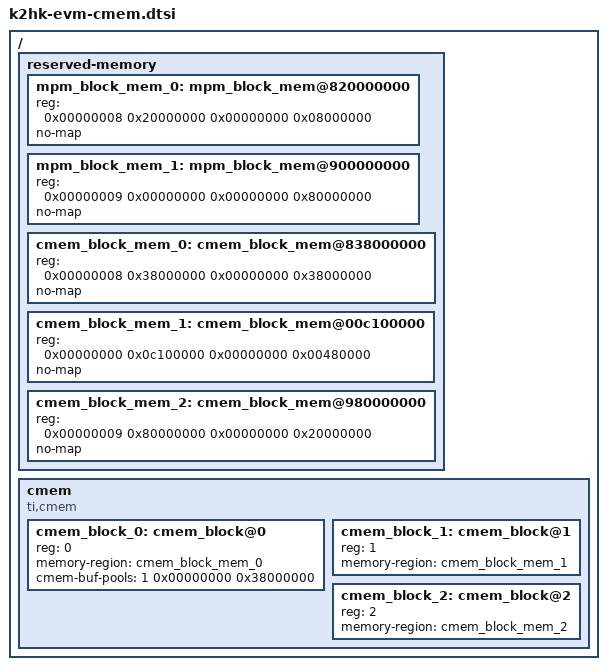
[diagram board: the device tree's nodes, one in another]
/ {
        reserved-memory {
                mpm_block_mem_0: mpm_block_mem@820000000 {
                        reg = <0x00000008 0x20000000 0x00000000 0x08000000>;
                        no-map;
                        status = "okay";
                };
                mpm_block_mem_1: mpm_block_mem@900000000 {
                        reg = <0x00000009 0x00000000 0x00000000 0x80000000>;
                        no-map;
                        status = "okay";
                };

                cmem_block_mem_0: cmem_block_mem@838000000 {
                        reg = <0x00000008 0x38000000 0x00000000 0x38000000>;
                        no-map;
                        status = "okay";
                };

                cmem_block_mem_1: cmem_block_mem@00c100000 {
                        reg = <0x00000000 0x0c100000 0x00000000 0x00480000>;
                        no-map;
                        status = "okay";
                };

                cmem_block_mem_2: cmem_block_mem@980000000 {
                        reg = <0x00000009 0x80000000 0x00000000 0x20000000>;
                        no-map;
                        status = "okay";
                };
        };

        cmem {
                compatible = "ti,cmem";
                #address-cells = <1>;
                #size-cells = <0>;

		#pool-size-cells = <2>;

                status = "okay";

                cmem_block_0: cmem_block@0 {
                        reg = <0>;
                        memory-region = <&cmem_block_mem_0>;
						cmem-buf-pools = <1 0x00000000 0x38000000>;
                };

                cmem_block_1: cmem_block@1 {
                        reg = <1>;
                        memory-region = <&cmem_block_mem_1>;
                };

                cmem_block_2: cmem_block@2 {
                        reg = <2>;
                        memory-region = <&cmem_block_mem_2>;
                };
        };

};
